# regs register map
File version: 1.0.0
Address unit: 16 bits
Registers are 32-bit, access per field, reset 0x0 unless marked. A register's access mark holds for its fields unless they carry their own. Offsets are from the block's base; lines under a group give offsets from that group; [hi:lo] are bit positions; {n}, {i} and the like mark numbered series; 'fields as' and 'values as' point back to an identical list; <NAME> marks a mode.

## Memory map
0x00000000 CSR blocks up to offset 0x42

## CSR
Base 0x00000000
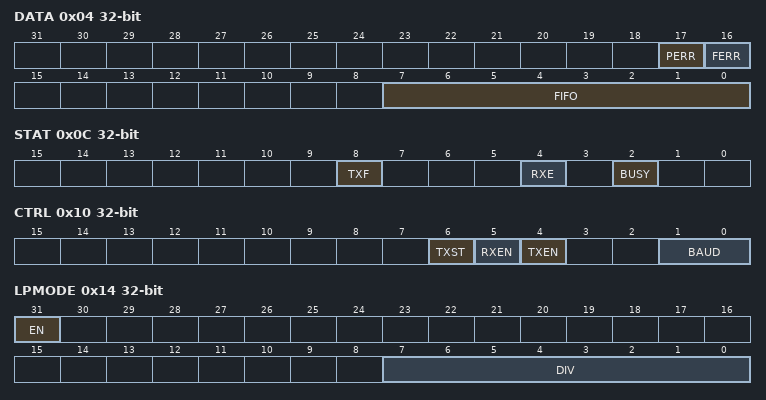
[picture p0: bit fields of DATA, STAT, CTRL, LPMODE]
0x04 DATA
  [17] PERR ro read-clears — Parity error flag. Read to clear.
  [16] FERR ro read-clears — Frame error flag. Read to clear.
  [7:0] FIFO rw — Write to push value to TX FIFO, read to get data from RX FIFO
0x0C STAT ro — Status register
  [8] TXF — TX FIFO is full
  [4] RXE — RX FIFO is empty
  [2] BUSY — Transciever is busy
0x10 CTRL — Control register
  [6] TXST wo — Force transmission start
  [5] RXEN rw — Receiver enable. Can be disabled by hardware on error.
  [4] TXEN rw — Transmitter enable. Can be disabled by hardware on error.
  [1:0] BAUD rw — Baudrate value
    0=B9600 (9600 baud); 1=B38400 (38400 baud); 2=B115200 (115200 baud)
0x14 LPMODE rw — Low power mode control
  [31] EN — Low power mode enable
  [7:0] DIV — Clock divider in low power mode
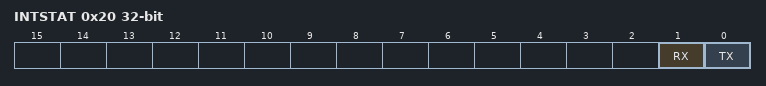
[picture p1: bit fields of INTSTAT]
0x20 INTSTAT rw — Interrupt status register
  [1] RX write-1-clears — Receiver interrupt. Write 1 to clear.
  [0] TX write-1-clears — Transmitter interrupt flag. Write 1 to clear.
0x40 ID ro reset 0xCAFE0666 — IP-core ID register
  [31:0] UID — Unique ID
